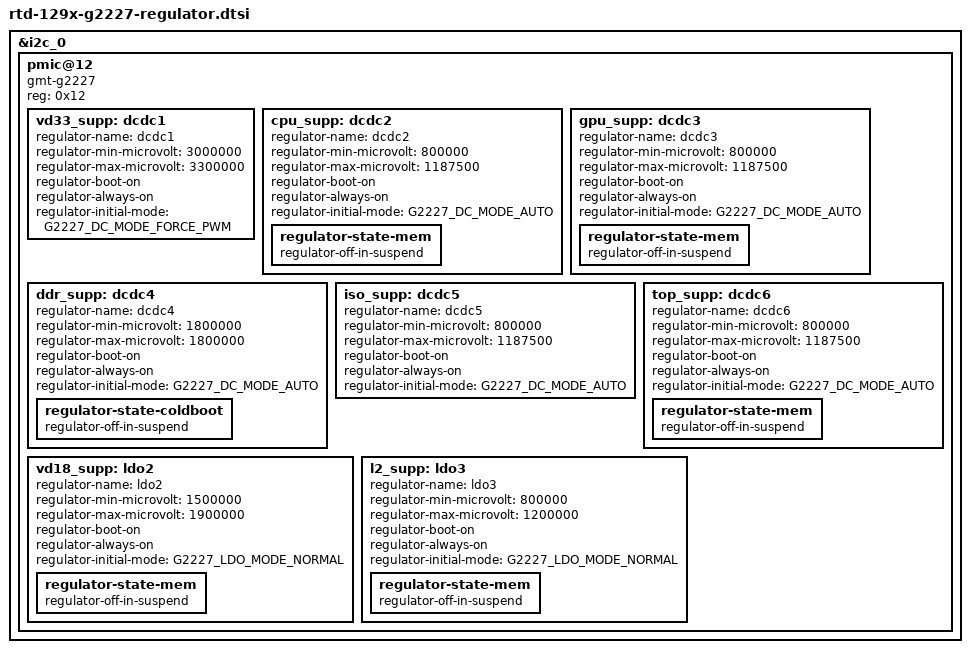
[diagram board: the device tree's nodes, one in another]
#include <dt-bindings/regulator/gmt,g2227.h>

&i2c_0 {
	pmic@12 {
		compatible = "gmt-g2227";
		reg = <0x12>;
		status = "okay";

		vd33_supp: dcdc1 {
			regulator-name = "dcdc1";
			regulator-min-microvolt = <3000000>;
			regulator-max-microvolt = <3300000>;

			regulator-boot-on;
			regulator-always-on;
			regulator-initial-mode = <G2227_DC_MODE_FORCE_PWM>;
		};

		cpu_supp: dcdc2 {
			regulator-name = "dcdc2";
			regulator-min-microvolt = <800000>;
			regulator-max-microvolt = <1187500>;

			regulator-boot-on;
			regulator-always-on;
			regulator-initial-mode = <G2227_DC_MODE_AUTO>;
			regulator-state-mem {
				regulator-off-in-suspend;
			};
		};
		gpu_supp: dcdc3 {
			regulator-name = "dcdc3";
			regulator-min-microvolt = <800000>;
			regulator-max-microvolt = <1187500>;

			regulator-boot-on;
			regulator-always-on;
			regulator-initial-mode = <G2227_DC_MODE_AUTO>;
			regulator-state-mem {
				regulator-off-in-suspend;
			};
		};
		ddr_supp: dcdc4 {
			regulator-name = "dcdc4";
			regulator-min-microvolt = <1800000>;
			regulator-max-microvolt = <1800000>;
			regulator-boot-on;
			regulator-always-on;
			regulator-initial-mode = <G2227_DC_MODE_AUTO>;
			regulator-state-coldboot {
				regulator-off-in-suspend;
			};

		};
		iso_supp: dcdc5 {
			regulator-name = "dcdc5";
			regulator-min-microvolt = <800000>;
			regulator-max-microvolt = <1187500>;

			regulator-boot-on;
			regulator-always-on;
			regulator-initial-mode = <G2227_DC_MODE_AUTO>;
		};
		top_supp: dcdc6 {
			regulator-name = "dcdc6";
			regulator-min-microvolt = <800000>;
			regulator-max-microvolt = <1187500>;

			regulator-boot-on;
			regulator-always-on;
			regulator-initial-mode = <G2227_DC_MODE_AUTO>;
			regulator-state-mem {
				regulator-off-in-suspend;
			};
		};
		vd18_supp: ldo2 {
			regulator-name = "ldo2";
			regulator-min-microvolt = <1500000>;
			regulator-max-microvolt = <1900000>;

			regulator-boot-on;
			regulator-always-on;
			regulator-initial-mode = <G2227_LDO_MODE_NORMAL>;
			regulator-state-mem {
				regulator-off-in-suspend;
			};
		};
		l2_supp: ldo3 {
			regulator-name = "ldo3";
			regulator-min-microvolt = <800000>;
			regulator-max-microvolt = <1200000>;

			regulator-boot-on;
			regulator-always-on;
			regulator-initial-mode = <G2227_LDO_MODE_NORMAL>;
			regulator-state-mem {
				regulator-off-in-suspend;
			};
		};
	};
}; /* i2c0 */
